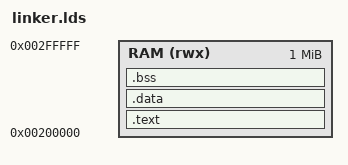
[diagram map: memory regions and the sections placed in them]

ENTRY(_start)

MEMORY
{
        RAM (rwx) : ORIGIN = 0x00200000, LENGTH = 1M
}

SECTIONS
{
        /**********************************************************************
         *                                                                    *
         **********************************************************************/
        .text :
        {
                _stext = .;
                *(.startup)
                *(.text)
                *(.text.*)
                *(.rodata)
                *(.rodata.*)
                *(.got1)
                *(.eh_frame)
                . = ALIGN(0x10);
                _etext = .;
        } > RAM
        /**********************************************************************
         *                                                                    *
         **********************************************************************/
        .data : AT(_etext)
        {
                _sdata = .;
                *(.data)
                *(.data.*)
                *(.sdata)
                _sdata2 = .;
                *(.sdata2)
                *(.got.plt)
                *(.got)
                . = ALIGN(0x10);
                _edata = .;
        } > RAM
        /**********************************************************************
         *                                                                    *
         **********************************************************************/
        .bss ADDR(.data) + SIZEOF(.data) (NOLOAD) :
        {
                _sbss = .;
                *(.bss)
                *(.bss.*)
                *(COMMON)
                *(.sbss)
                *(.sbss.*)
                *(.scommon)
                *(.dynbss)
                . = ALIGN(0x10);
                _ebss = .;
        } > RAM
        /**********************************************************************
         *                                                                    *
         **********************************************************************/
        .debug_info     : { *(.debug_info) }
        .debug_abbrev   : { *(.debug_abbrev) }
        .debug_aranges  : { *(.debug_aranges) }
        .debug_frame    : { *(.debug_frame) }
        .debug_line     : { *(.debug_line) }
        .debug_line_str : { *(.debug_line_str) }
        .debug_loclists : { *(.debug_loclists) }
        .debug_macro    : { *(.debug_macro) }
        .debug_names    : { *(.debug_names) }
        .debug_rnglists : { *(.debug_rnglists) }
        .debug_str      : { *(.debug_str) }
        /**********************************************************************
         *                                                                    *
         **********************************************************************/
        /DISCARD/ :
        {
                *(.comment)
        }
}

